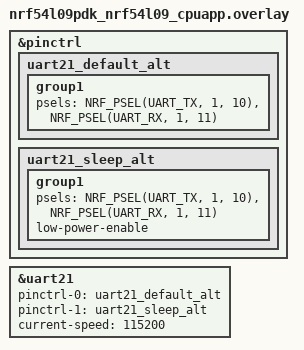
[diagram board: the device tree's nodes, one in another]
/* SPDX-License-Identifier: Apache-2.0 */

&pinctrl {
	uart21_default_alt: uart21_default_alt {
		group1 {
			psels = <NRF_PSEL(UART_TX, 1, 10)>,
				<NRF_PSEL(UART_RX, 1, 11)>;
		};
	};

	uart21_sleep_alt: uart21_sleep_alt {
		group1 {
			psels = <NRF_PSEL(UART_TX, 1, 10)>,
				<NRF_PSEL(UART_RX, 1, 11)>;
			low-power-enable;
		};
	};
};

dut: &uart21 {
	status = "okay";
	pinctrl-0 = <&uart21_default_alt>;
	pinctrl-1 = <&uart21_sleep_alt>;
	pinctrl-names = "default", "sleep";
	current-speed = <115200>;
};
